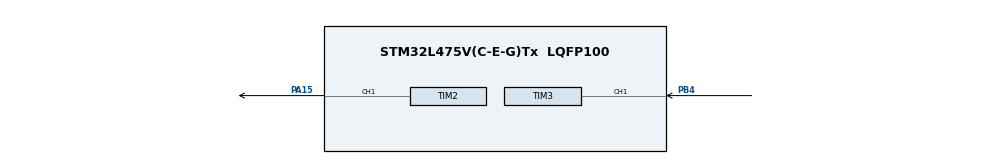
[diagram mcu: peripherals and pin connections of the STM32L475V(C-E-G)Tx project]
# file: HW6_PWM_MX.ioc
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Mcu.Family=STM32L4
Mcu.Name=STM32L475V(C-E-G)Tx
Mcu.Package=LQFP100
NVIC.PriorityGroup=NVIC_PRIORITYGROUP_4
NVIC.TIM3_IRQn=true\:0\:0\:false\:false\:true\:true\:true\:true
PA13\ (JTMS-SWDIO).Mode=Serial_Wire
PA13\ (JTMS-SWDIO).Signal=SYS_JTMS-SWDIO
PA14\ (JTCK-SWCLK).Mode=Serial_Wire
PA14\ (JTCK-SWCLK).Signal=SYS_JTCK-SWCLK
PA15\ (JTDI).Signal=S_TIM2_CH1
PB4\ (NJTRST).Signal=S_TIM3_CH1
ProjectManager.HeapSize=0x200
ProjectManager.StackSize=0x400
ProjectManager.TargetToolchain=STM32CubeIDE
RCC.HSE_VALUE=8000000
RCC.HSI_VALUE=16000000
RCC.LSE_VALUE=32768
RCC.MSI_VALUE=4000000
RCC.VCOOutputFreq_Value=32000000
SH.S_TIM2_CH1.0=TIM2_CH1,PWM Generation1 CH1
SH.S_TIM3_CH1.0=TIM3_CH1,Input_Capture1_from_TI1
TIM2.Channel-PWM\ Generation1\ CH1=TIM_CHANNEL_1
TIM2.Period=999
TIM2.Prescaler=3
TIM2.Pulse-PWM\ Generation1\ CH1=250
TIM3.Channel-Input_Capture1_from_TI1=TIM_CHANNEL_1
TIM3.ICPolarity_CH1=TIM_INPUTCHANNELPOLARITY_BOTHEDGE
TIM3.Prescaler=3
VP_TIM2_VS_ClockSourceINT.Mode=Internal
VP_TIM3_VS_ClockSourceINT.Mode=Internal
board=custom

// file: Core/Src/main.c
/* USER CODE BEGIN Header */
/**
  ******************************************************************************
  * @file           : main.c
  * @brief          : Main program body
  ******************************************************************************
  * @attention
  *
  * Copyright (c) 2026 STMicroelectronics.
  * All rights reserved.
  *
  * This software is licensed under terms that can be found in the LICENSE file
  * in the root directory of this software component.
  * If no LICENSE file comes with this software, it is provided AS-IS.
  *
  ******************************************************************************
  */
/* USER CODE END Header */
#include "main.h"

TIM_HandleTypeDef htim2;
TIM_HandleTypeDef htim3;

/* USER CODE BEGIN PV */
volatile uint32_t measured_frequency_hz = 0;
volatile uint32_t measured_duty_percent = 0;
volatile uint32_t measured_period_us = 0;
volatile uint32_t measured_high_us = 0;
/* USER CODE END PV */

void SystemClock_Config(void);
static void MX_GPIO_Init(void);
static void MX_TIM2_Init(void);
static void MX_TIM3_Init(void);

int main(void)
{

  /* MCU Configuration--------------------------------------------------------*/

  /* Reset of all peripherals, Initializes the Flash interface and the Systick. */
  HAL_Init();

  /* Configure the system clock */
  SystemClock_Config();

  /* Initialize all configured peripherals */
  MX_GPIO_Init();
  MX_TIM2_Init();
  MX_TIM3_Init();
  /* USER CODE BEGIN 2 */

  HAL_TIM_PWM_Start(&htim2, TIM_CHANNEL_1);
  HAL_TIM_IC_Start_IT(&htim3, TIM_CHANNEL_1);

  /* USER CODE END 2 */

  /* Infinite loop */
  while (1)
  {

    /* USER CODE BEGIN 3 */

	  __HAL_TIM_SET_COMPARE(&htim2, TIM_CHANNEL_1, 250);
	  HAL_Delay(5000);

	  __HAL_TIM_SET_COMPARE(&htim2, TIM_CHANNEL_1, 500);
	  HAL_Delay(5000);

	  __HAL_TIM_SET_COMPARE(&htim2, TIM_CHANNEL_1, 750);
	  HAL_Delay(5000);
  }
  /* USER CODE END 3 */
}

void SystemClock_Config(void)
{
  RCC_OscInitTypeDef RCC_OscInitStruct = {0};
  RCC_ClkInitTypeDef RCC_ClkInitStruct = {0};

  /** Configure the main internal regulator output voltage
  */
  if (HAL_PWREx_ControlVoltageScaling(PWR_REGULATOR_VOLTAGE_SCALE1) != HAL_OK)
  {
    Error_Handler();
  }

  /** Initializes the RCC Oscillators according to the specified parameters
  * in the RCC_OscInitTypeDef structure.
  */
  RCC_OscInitStruct.OscillatorType = RCC_OSCILLATORTYPE_MSI;
  RCC_OscInitStruct.MSIState = RCC_MSI_ON;
  RCC_OscInitStruct.MSICalibrationValue = 0;
  RCC_OscInitStruct.MSIClockRange = RCC_MSIRANGE_6;
  RCC_OscInitStruct.PLL.PLLState = RCC_PLL_NONE;
  if (HAL_RCC_OscConfig(&RCC_OscInitStruct) != HAL_OK)
  {
    Error_Handler();
  }

  /** Initializes the CPU, AHB and APB buses clocks
  */
  RCC_ClkInitStruct.ClockType = RCC_CLOCKTYPE_HCLK|RCC_CLOCKTYPE_SYSCLK
                              |RCC_CLOCKTYPE_PCLK1|RCC_CLOCKTYPE_PCLK2;
  RCC_ClkInitStruct.SYSCLKSource = RCC_SYSCLKSOURCE_MSI;
  RCC_ClkInitStruct.AHBCLKDivider = RCC_SYSCLK_DIV1;
  RCC_ClkInitStruct.APB1CLKDivider = RCC_HCLK_DIV1;
  RCC_ClkInitStruct.APB2CLKDivider = RCC_HCLK_DIV1;

  if (HAL_RCC_ClockConfig(&RCC_ClkInitStruct, FLASH_LATENCY_0) != HAL_OK)
  {
    Error_Handler();
  }
}

static void MX_TIM2_Init(void)
{

  TIM_ClockConfigTypeDef sClockSourceConfig = {0};
  TIM_MasterConfigTypeDef sMasterConfig = {0};
  TIM_OC_InitTypeDef sConfigOC = {0};

  htim2.Instance = TIM2;
  htim2.Init.Prescaler = 3;
  htim2.Init.CounterMode = TIM_COUNTERMODE_UP;
  htim2.Init.Period = 999;
  htim2.Init.ClockDivision = TIM_CLOCKDIVISION_DIV1;
  htim2.Init.AutoReloadPreload = TIM_AUTORELOAD_PRELOAD_DISABLE;
  if (HAL_TIM_Base_Init(&htim2) != HAL_OK)
  {
    Error_Handler();
  }
  sClockSourceConfig.ClockSource = TIM_CLOCKSOURCE_INTERNAL;
  if (HAL_TIM_ConfigClockSource(&htim2, &sClockSourceConfig) != HAL_OK)
  {
    Error_Handler();
  }
  if (HAL_TIM_PWM_Init(&htim2) != HAL_OK)
  {
    Error_Handler();
  }
  sMasterConfig.MasterOutputTrigger = TIM_TRGO_RESET;
  sMasterConfig.MasterSlaveMode = TIM_MASTERSLAVEMODE_DISABLE;
  if (HAL_TIMEx_MasterConfigSynchronization(&htim2, &sMasterConfig) != HAL_OK)
  {
    Error_Handler();
  }
  sConfigOC.OCMode = TIM_OCMODE_PWM1;
  sConfigOC.Pulse = 250;
  sConfigOC.OCPolarity = TIM_OCPOLARITY_HIGH;
  sConfigOC.OCFastMode = TIM_OCFAST_DISABLE;
  if (HAL_TIM_PWM_ConfigChannel(&htim2, &sConfigOC, TIM_CHANNEL_1) != HAL_OK)
  {
    Error_Handler();
  }
  HAL_TIM_MspPostInit(&htim2);

}

static void MX_TIM3_Init(void)
{

  TIM_ClockConfigTypeDef sClockSourceConfig = {0};
  TIM_MasterConfigTypeDef sMasterConfig = {0};
  TIM_IC_InitTypeDef sConfigIC = {0};

  htim3.Instance = TIM3;
  htim3.Init.Prescaler = 3;
  htim3.Init.CounterMode = TIM_COUNTERMODE_UP;
  htim3.Init.Period = 65535;
  htim3.Init.ClockDivision = TIM_CLOCKDIVISION_DIV1;
  htim3.Init.AutoReloadPreload = TIM_AUTORELOAD_PRELOAD_DISABLE;
  if (HAL_TIM_Base_Init(&htim3) != HAL_OK)
  {
    Error_Handler();
  }
  sClockSourceConfig.ClockSource = TIM_CLOCKSOURCE_INTERNAL;
  if (HAL_TIM_ConfigClockSource(&htim3, &sClockSourceConfig) != HAL_OK)
  {
    Error_Handler();
  }
  if (HAL_TIM_IC_Init(&htim3) != HAL_OK)
  {
    Error_Handler();
  }
  sMasterConfig.MasterOutputTrigger = TIM_TRGO_RESET;
  sMasterConfig.MasterSlaveMode = TIM_MASTERSLAVEMODE_DISABLE;
  if (HAL_TIMEx_MasterConfigSynchronization(&htim3, &sMasterConfig) != HAL_OK)
  {
    Error_Handler();
  }
  sConfigIC.ICPolarity = TIM_INPUTCHANNELPOLARITY_BOTHEDGE;
  sConfigIC.ICSelection = TIM_ICSELECTION_DIRECTTI;
  sConfigIC.ICPrescaler = TIM_ICPSC_DIV1;
  sConfigIC.ICFilter = 0;
  if (HAL_TIM_IC_ConfigChannel(&htim3, &sConfigIC, TIM_CHANNEL_1) != HAL_OK)
  {
    Error_Handler();
  }

}

static void MX_GPIO_Init(void)
{

  /* GPIO Ports Clock Enable */
  __HAL_RCC_GPIOA_CLK_ENABLE();
  __HAL_RCC_GPIOB_CLK_ENABLE();

}

/* USER CODE BEGIN 4 */
void HAL_TIM_IC_CaptureCallback(TIM_HandleTypeDef *htim)
{
    static uint16_t last_rising = 0;
    static uint16_t high_ticks = 0;
    static uint8_t have_rising = 0;
    static uint8_t have_falling = 0;

    if (htim->Instance != TIM3 ||
        htim->Channel != HAL_TIM_ACTIVE_CHANNEL_1)
    {
        return;
    }

    uint16_t captured = (uint16_t)
        HAL_TIM_ReadCapturedValue(htim, TIM_CHANNEL_1);

    if (HAL_GPIO_ReadPin(GPIOB, GPIO_PIN_4) == GPIO_PIN_SET)
    {
        // Rising edge
        if (have_rising && have_falling)
        {
            uint16_t period_ticks =
                (uint16_t)(captured - last_rising);

            if (period_ticks > 0 && high_ticks <= period_ticks)
            {
                measured_period_us = period_ticks;
                measured_high_us = high_ticks;

                measured_frequency_hz =
                    1000000U / period_ticks;

                measured_duty_percent =
                    ((uint32_t)high_ticks * 100U +
                     period_ticks / 2U) / period_ticks;
            }
        }

        last_rising = captured;
        have_rising = 1;
        have_falling = 0;
    }
    else
    {
        // Falling edge
        if (have_rising)
        {
            high_ticks =
                (uint16_t)(captured - last_rising);

            have_falling = 1;
        }
    }
}
/* USER CODE END 4 */

void Error_Handler(void)
{
  __disable_irq();
  while (1)
  {
  }
}
